AUTOSAR XML (schema 4-0-3)
package /ComponentTypes
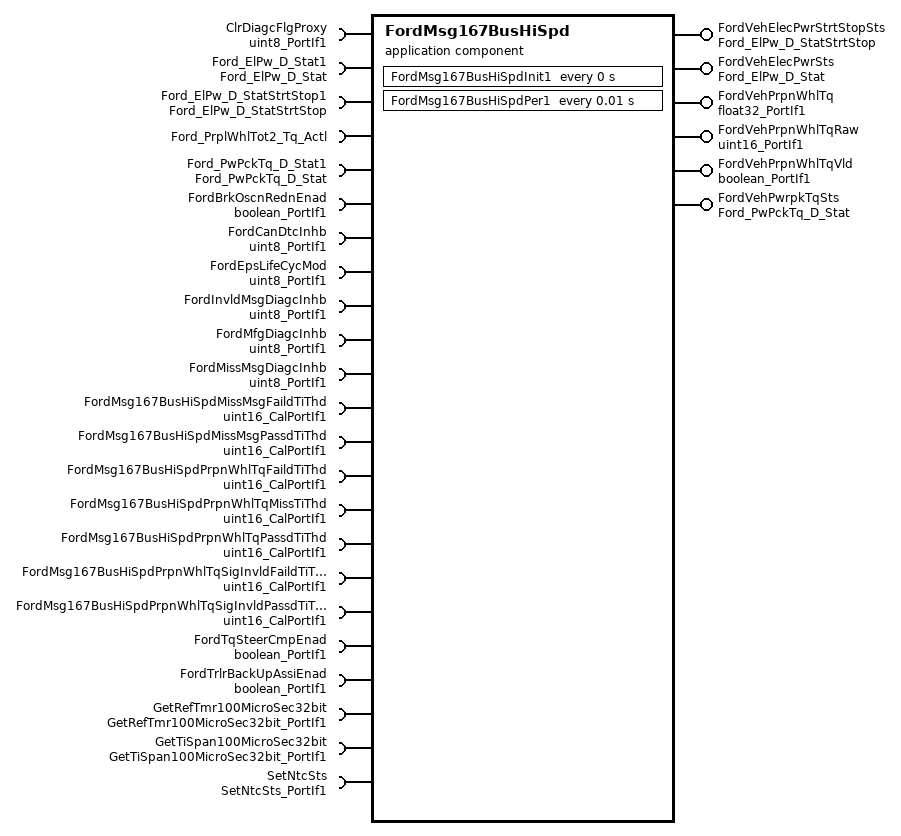
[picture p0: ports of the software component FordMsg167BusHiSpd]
  application sw component type FordMsg167BusHiSpd
    6 x provide port:
      FordVehElecPwrStrtStopSts: nonqueued-sender-com-spec{data-element=Ford_ElPw_D_StatStrtStop, init-value=0}, provided-interface=Ford_ElPw_D_StatStrtStop
      FordVehElecPwrSts: nonqueued-sender-com-spec{data-element=Ford_ElPw_D_Stat, init-value=0}, provided-interface=Ford_ElPw_D_Stat
      FordVehPrpnWhlTq: nonqueued-sender-com-spec{data-element=Val, init-value=-131072.0}, provided-interface=float32_PortIf1
      FordVehPrpnWhlTqRaw: nonqueued-sender-com-spec{data-element=Val, init-value=0}, provided-interface=uint16_PortIf1
      FordVehPrpnWhlTqVld: nonqueued-sender-com-spec{data-element=Logl, init-value=0}, provided-interface=boolean_PortIf1
      FordVehPwrpkTqSts: nonqueued-sender-com-spec{data-element=Ford_PwPckTq_D_Stat, init-value=0}, provided-interface=Ford_PwPckTq_D_Stat
    23 x require port:
      ClrDiagcFlgProxy: nonqueued-receiver-com-spec{data-element=Val, filter=data-filter-type=ALWAYS, init-value=0}, required-interface=uint8_PortIf1
      Ford_ElPw_D_Stat1: nonqueued-receiver-com-spec{data-element=Ford_ElPw_D_Stat, filter=data-filter-type=ALWAYS, init-value=0}, required-interface=Ford_ElPw_D_Stat
      Ford_ElPw_D_StatStrtStop1: nonqueued-receiver-com-spec{data-element=Ford_ElPw_D_StatStrtStop, filter=data-filter-type=ALWAYS, init-value=0}, required-interface=Ford_ElPw_D_StatStrtStop
      Ford_PrplWhlTot2_Tq_Actl: nonqueued-receiver-com-spec{data-element=Ford_PrplWhlTot2_Tq_Actl, filter=data-filter-type=ALWAYS, init-value=0}, required-interface=Ford_PrplWhlTot2_Tq_Actl
      Ford_PwPckTq_D_Stat1: nonqueued-receiver-com-spec{data-element=Ford_PwPckTq_D_Stat, filter=data-filter-type=ALWAYS, init-value=0}, required-interface=Ford_PwPckTq_D_Stat
      FordBrkOscnRednEnad: nonqueued-receiver-com-spec{data-element=Logl, filter=data-filter-type=ALWAYS, init-value=0}, required-interface=boolean_PortIf1
      FordCanDtcInhb: nonqueued-receiver-com-spec{data-element=Val, filter=data-filter-type=ALWAYS, init-value=1}, required-interface=uint8_PortIf1
      FordEpsLifeCycMod: nonqueued-receiver-com-spec{data-element=Val, filter=data-filter-type=ALWAYS, init-value=0}, required-interface=uint8_PortIf1
      FordInvldMsgDiagcInhb: nonqueued-receiver-com-spec{data-element=Val, filter=data-filter-type=ALWAYS, init-value=0}, required-interface=uint8_PortIf1
      FordMfgDiagcInhb: nonqueued-receiver-com-spec{data-element=Val, filter=data-filter-type=ALWAYS, init-value=0}, required-interface=uint8_PortIf1
      FordMissMsgDiagcInhb: nonqueued-receiver-com-spec{data-element=Val, filter=data-filter-type=ALWAYS, init-value=0}, required-interface=uint8_PortIf1
      FordMsg167BusHiSpdMissMsgFaildTiThd: parameter-require-com-spec{init-value=100, parameter=Val}, required-interface=uint16_CalPortIf1
      FordMsg167BusHiSpdMissMsgPassdTiThd: parameter-require-com-spec{init-value=0, parameter=Val}, required-interface=uint16_CalPortIf1
      FordMsg167BusHiSpdPrpnWhlTqFaildTiThd: parameter-require-com-spec{init-value=5000, parameter=Val}, required-interface=uint16_CalPortIf1
      FordMsg167BusHiSpdPrpnWhlTqMissTiThd: parameter-require-com-spec{init-value=0, parameter=Val}, required-interface=uint16_CalPortIf1
      FordMsg167BusHiSpdPrpnWhlTqPassdTiThd: parameter-require-com-spec{init-value=5000, parameter=Val}, required-interface=uint16_CalPortIf1
      FordMsg167BusHiSpdPrpnWhlTqSigInvldFaildTiThd: parameter-require-com-spec{init-value=0, parameter=Val}, required-interface=uint16_CalPortIf1
      FordMsg167BusHiSpdPrpnWhlTqSigInvldPassdTiThd: parameter-require-com-spec{init-value=0, parameter=Val}, required-interface=uint16_CalPortIf1
      FordTqSteerCmpEnad: nonqueued-receiver-com-spec{data-element=Logl, filter=data-filter-type=ALWAYS, init-value=0}, required-interface=boolean_PortIf1
      FordTrlrBackUpAssiEnad: nonqueued-receiver-com-spec{data-element=Logl, filter=data-filter-type=ALWAYS, init-value=0}, required-interface=boolean_PortIf1
      GetRefTmr100MicroSec32bit: client-com-spec=Oper, required-interface=GetRefTmr100MicroSec32bit_PortIf1
      GetTiSpan100MicroSec32bit: client-com-spec=Oper, required-interface=GetTiSpan100MicroSec32bit_PortIf1
      SetNtcSts: client-com-spec=Oper, required-interface=SetNtcSts_PortIf1
    behavior FordMsg167BusHiSpd_InternalBehavior
      ar-typed-per-instance-memorys:
        17 x data, all with sw-calibration-access=READ-ONLY:
          ClrDiagcFlgProxyPrev: type=uint8
          FirstTranVldFlg: type=boolean
          FordVehElecPwrStrtStopStsPrev: type=Ford_ElPw_D_StatStrtStop
          FordVehElecPwrStsPrev: type=Ford_ElPw_D_Stat
          FordVehMsg167Miss: type=boolean
          FordVehMsg167Rxd: type=boolean
          FordVehPrpnWhlTqPrev: type=float32
          FordVehPrpnWhlTqRawPrev: type=uint16
          FordVehPrpnWhlTqSigInvldFaildRefTi: type=uint32
          FordVehPrpnWhlTqSigInvldPassdRefTi: type=uint32
          FordVehPrpnWhlTqVldPrev: type=boolean
          FordVehPwrpkTqStsPrev: type=Ford_PwPckTq_D_Stat
          MissMsgFaildRefTi: type=uint32
          MissMsgPassdRefTi: type=uint32
          PrpnWhlTqVldFaildRefTi: type=uint32
          PrpnWhlTqVldMissRefTi: type=uint32
          PrpnWhlTqVldPassdRefTi: type=uint32
      timing event FordMsg167BusHiSpdInit1_InitEvent: start-on-event=FordMsg167BusHiSpdInit1, period=0
      timing event TMT_FordMsg167BusHiSpdPer1: start-on-event=FordMsg167BusHiSpdPer1, period=0.01
      port-api-options:
        enable-take-address=false, indirect-api=false, port=ClrDiagcFlgProxy
        enable-take-address=false, indirect-api=false, port=Ford_ElPw_D_Stat1
        enable-take-address=false, indirect-api=false, port=Ford_ElPw_D_StatStrtStop1
        enable-take-address=false, indirect-api=false, port=Ford_PrplWhlTot2_Tq_Actl
        enable-take-address=false, indirect-api=false, port=Ford_PwPckTq_D_Stat1
        enable-take-address=false, indirect-api=false, port=FordBrkOscnRednEnad
        enable-take-address=false, indirect-api=false, port=FordCanDtcInhb
        enable-take-address=false, indirect-api=false, port=FordEpsLifeCycMod
        enable-take-address=false, indirect-api=false, port=FordInvldMsgDiagcInhb
        enable-take-address=false, indirect-api=false, port=FordMfgDiagcInhb
        enable-take-address=false, indirect-api=false, port=FordMissMsgDiagcInhb
        enable-take-address=false, indirect-api=false, port=FordMsg167BusHiSpdMissMsgFaildTiThd
        enable-take-address=false, indirect-api=false, port=FordMsg167BusHiSpdMissMsgPassdTiThd
        enable-take-address=false, indirect-api=false, port=FordMsg167BusHiSpdPrpnWhlTqFaildTiThd
        enable-take-address=false, indirect-api=false, port=FordMsg167BusHiSpdPrpnWhlTqMissTiThd
        enable-take-address=false, indirect-api=false, port=FordMsg167BusHiSpdPrpnWhlTqPassdTiThd
        enable-take-address=false, indirect-api=false, port=FordMsg167BusHiSpdPrpnWhlTqSigInvldFaildTiThd
        enable-take-address=false, indirect-api=false, port=FordMsg167BusHiSpdPrpnWhlTqSigInvldPassdTiThd
        enable-take-address=false, indirect-api=false, port=FordTqSteerCmpEnad
        enable-take-address=false, indirect-api=false, port=FordTrlrBackUpAssiEnad
        enable-take-address=false, indirect-api=false, port=FordVehElecPwrStrtStopSts
        enable-take-address=false, indirect-api=false, port=FordVehElecPwrSts
        enable-take-address=false, indirect-api=false, port=FordVehPrpnWhlTq
        enable-take-address=false, indirect-api=false, port=FordVehPrpnWhlTqRaw
        enable-take-address=false, indirect-api=false, port=FordVehPrpnWhlTqVld
        enable-take-address=false, indirect-api=false, port=FordVehPwrpkTqSts
        enable-take-address=false, indirect-api=false, port=GetRefTmr100MicroSec32bit
        enable-take-address=false, indirect-api=false, port=GetTiSpan100MicroSec32bit
        enable-take-address=false, indirect-api=false, port=SetNtcSts
      runnable FordMsg167BusHiSpdInit1
        sync call SC_GetRefTmr100MicroSec32bit_PortIf1_Oper: operation=GetRefTmr100MicroSec32bit.Oper, timeout=0
      runnable FordMsg167BusHiSpdPer1
        data-receive-point-by-arguments:
          13 x access:
            REC_ClrDiagcFlgProxy_Val: accessed-variable=ClrDiagcFlgProxy.Val
            REC_Ford_ElPw_D_Stat1_Ford_ElPw_D_Stat: accessed-variable=Ford_ElPw_D_Stat1.Ford_ElPw_D_Stat
            REC_Ford_ElPw_D_StatStrtStop1_Ford_ElPw_D_StatStrtStop: accessed-variable=Ford_ElPw_D_StatStrtStop1.Ford_ElPw_D_StatStrtStop
            REC_Ford_PrplWhlTot2_Tq_Actl_Ford_PrplWhlTot2_Tq_Actl: accessed-variable=Ford_PrplWhlTot2_Tq_Actl.Ford_PrplWhlTot2_Tq_Actl
            REC_FordBrkOscnRednEnad_Logl: accessed-variable=FordBrkOscnRednEnad.Logl
            REC_FordCanDtcInhb_Val: accessed-variable=FordCanDtcInhb.Val
            REC_FordEpsLifeCycMod_Val: accessed-variable=FordEpsLifeCycMod.Val
            REC_FordInvldMsgDiagcInhb_Val: accessed-variable=FordInvldMsgDiagcInhb.Val
            REC_FordMfgDiagcInhb_Val: accessed-variable=FordMfgDiagcInhb.Val
            REC_FordMissMsgDiagcInhb_Val: accessed-variable=FordMissMsgDiagcInhb.Val
            REC_FordTqSteerCmpEnad_Logl: accessed-variable=FordTqSteerCmpEnad.Logl
            REC_FordTrlrBackUpAssiEnad_Logl: accessed-variable=FordTrlrBackUpAssiEnad.Logl
            SEND_Ford_PwPckTq_D_Stat1_Ford_PwPckTq_D_Stat: accessed-variable=Ford_PwPckTq_D_Stat1.Ford_PwPckTq_D_Stat
        data-send-points:
          6 x access:
            SEND_FordVehElecPwrStrtStopSts_Ford_ElPw_D_StatStrtStop: accessed-variable=FordVehElecPwrStrtStopSts.Ford_ElPw_D_StatStrtStop
            SEND_FordVehElecPwrSts_Ford_ElPw_D_Stat: accessed-variable=FordVehElecPwrSts.Ford_ElPw_D_Stat
            SEND_FordVehPrpnWhlTq_Val: accessed-variable=FordVehPrpnWhlTq.Val
            SEND_FordVehPrpnWhlTqRaw_Val: accessed-variable=FordVehPrpnWhlTqRaw.Val
            SEND_FordVehPrpnWhlTqVld_Logl: accessed-variable=FordVehPrpnWhlTqVld.Logl
            SEND_FordVehPwrpkTqSts_Ford_PwPckTq_D_Stat: accessed-variable=FordVehPwrpkTqSts.Ford_PwPckTq_D_Stat
        sync call SC_GetRefTmr100MicroSec32bit_PortIf1_Oper: operation=GetRefTmr100MicroSec32bit.Oper, timeout=0
        sync call SC_GetTiSpan100MicroSec32bit_PortIf1_Oper: operation=GetTiSpan100MicroSec32bit.Oper, timeout=0
        sync call SC_SetNtcSts_PortIf1_Oper: operation=SetNtcSts.Oper, timeout=0
  swc implementation FordMsg167BusHiSpd_Implementation: behavior=FordMsg167BusHiSpd_InternalBehavior
    code-descriptors:
      code Default: artifact-descriptors=autosar-engineering-object={short-label=Default, category=SWSRC}
